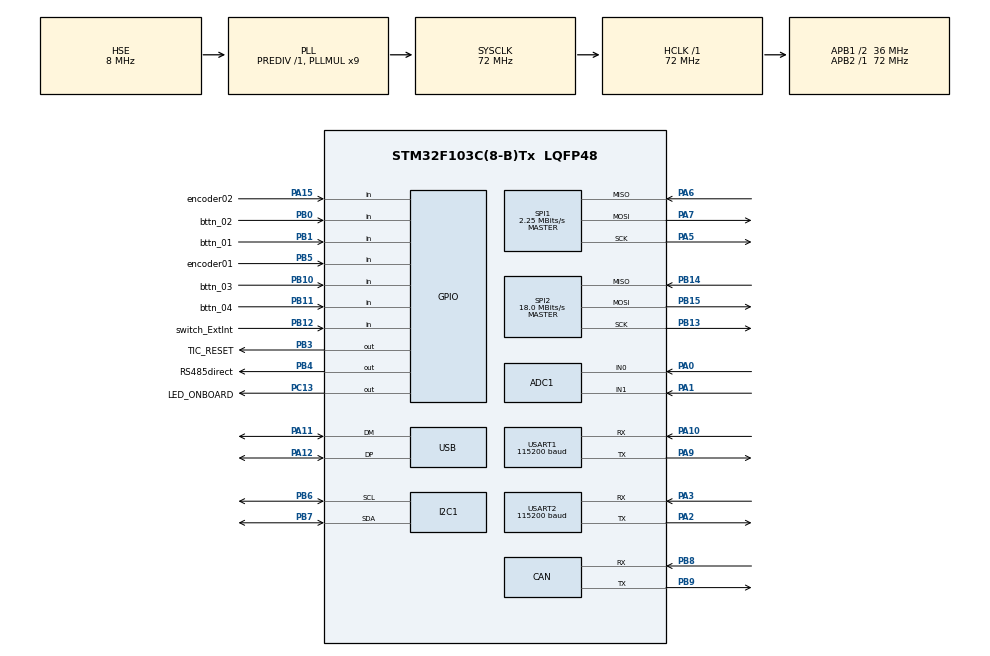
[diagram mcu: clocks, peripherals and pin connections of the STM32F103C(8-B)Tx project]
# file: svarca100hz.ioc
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ADC1.Channel-0\#ChannelRegularConversion=ADC_CHANNEL_0
ADC1.NbrOfConversionFlag=1
ADC1.Rank-0\#ChannelRegularConversion=1
ADC1.SamplingTime-0\#ChannelRegularConversion=ADC_SAMPLETIME_1CYCLE_5
ADC1.master=1
CAN.CalculateTimeBit=1333
CAN.CalculateTimeQuantum=444.44444444444446
Dma.I2C1_TX.1.Direction=DMA_MEMORY_TO_PERIPH
Dma.I2C1_TX.1.Instance=DMA1_Channel6
Dma.I2C1_TX.1.MemDataAlignment=DMA_MDATAALIGN_BYTE
Dma.I2C1_TX.1.MemInc=DMA_MINC_ENABLE
Dma.I2C1_TX.1.Mode=DMA_NORMAL
Dma.I2C1_TX.1.PeriphDataAlignment=DMA_PDATAALIGN_BYTE
Dma.I2C1_TX.1.PeriphInc=DMA_PINC_DISABLE
Dma.I2C1_TX.1.Priority=DMA_PRIORITY_LOW
Dma.Request0=SPI1_TX
Dma.Request1=I2C1_TX
Dma.SPI1_TX.0.Direction=DMA_MEMORY_TO_PERIPH
Dma.SPI1_TX.0.Instance=DMA1_Channel3
Dma.SPI1_TX.0.MemDataAlignment=DMA_MDATAALIGN_BYTE
Dma.SPI1_TX.0.MemInc=DMA_MINC_ENABLE
Dma.SPI1_TX.0.Mode=DMA_NORMAL
Dma.SPI1_TX.0.PeriphDataAlignment=DMA_PDATAALIGN_BYTE
Dma.SPI1_TX.0.PeriphInc=DMA_PINC_DISABLE
Dma.SPI1_TX.0.Priority=DMA_PRIORITY_LOW
FREERTOS.HEAP_NUMBER=1
FREERTOS.INCLUDE_vTaskDelete=0
FREERTOS.Tasks01=defaultTask,0,128,StartDefaultTask,Default,NULL,Dynamic,NULL,NULL;LedTask,0,128,StartLedTask,Default,NULL,Dynamic,NULL,NULL;lcd_Task,-2,256,Start_lcd_Task,Default,NULL,Dynamic,NULL,NULL;apl_Task,0,256,Start_apl_Task,Default,NULL,Dynamic,NULL,NULL
FREERTOS.Timers01=timer01,timer01_callback,osTimerOnce,Default,NULL,Dynamic,NULL
FREERTOS.configTOTAL_HEAP_SIZE=6000
FREERTOS.configUSE_TIMERS=1
I2C1.I2C_Mode=I2C_Standard
Mcu.Family=STM32F1
Mcu.Name=STM32F103C(8-B)Tx
Mcu.Package=LQFP48
NVIC.ADC1_2_IRQn=true\:5\:0\:false\:false\:true\:true\:true
NVIC.DMA1_Channel3_IRQn=true\:5\:0\:false\:false\:true\:true\:true
NVIC.DMA1_Channel6_IRQn=true\:5\:0\:false\:false\:true\:true\:true
NVIC.I2C1_EV_IRQn=true\:5\:0\:false\:false\:true\:true\:true
NVIC.PriorityGroup=NVIC_PRIORITYGROUP_4
NVIC.TIM1_UP_IRQn=true\:5\:0\:false\:false\:true\:true\:true
NVIC.TIM2_IRQn=true\:0\:0\:false\:false\:true\:false\:true
NVIC.TimeBase=TIM2_IRQn
NVIC.TimeBaseIP=TIM2
NVIC.USART1_IRQn=true\:5\:0\:false\:false\:true\:true\:true
NVIC.USART2_IRQn=true\:5\:0\:false\:false\:true\:true\:true
NVIC.USB_LP_CAN1_RX0_IRQn=true\:0\:0\:false\:false\:true\:false\:true
PA0-WKUP.Signal=ADCx_IN0
PA1.Signal=ADCx_IN1
PA10.Mode=Asynchronous
PA10.Signal=USART1_RX
PA11.Mode=Device
PA11.Signal=USB_DM
PA12.Mode=Device
PA12.Signal=USB_DP
PA13.Mode=Serial_Wire
PA13.Signal=SYS_JTMS-SWDIO
PA14.Mode=Serial_Wire
PA14.Signal=SYS_JTCK-SWCLK
PA15.GPIO_Label=encoder02
PA15.GPIO_PuPd=GPIO_PULLUP
PA15.Signal=GPIO_Input
PA2.Mode=Asynchronous
PA2.Signal=USART2_TX
PA3.Mode=Asynchronous
PA3.Signal=USART2_RX
PA5.Mode=Full_Duplex_Master
PA5.Signal=SPI1_SCK
PA6.Mode=Full_Duplex_Master
PA6.Signal=SPI1_MISO
PA7.Mode=Full_Duplex_Master
PA7.Signal=SPI1_MOSI
PA9.Mode=Asynchronous
PA9.Signal=USART1_TX
PB0.GPIO_Label=bttn_02
PB0.GPIO_PuPd=GPIO_PULLUP
PB0.Signal=GPIO_Input
PB1.GPIO_Label=bttn_01
PB1.GPIO_PuPd=GPIO_PULLUP
PB1.Signal=GPIO_Input
PB10.GPIO_Label=bttn_03
PB10.GPIO_PuPd=GPIO_PULLUP
PB10.Signal=GPIO_Input
PB11.GPIO_Label=bttn_04
PB11.GPIO_PuPd=GPIO_PULLUP
PB11.Signal=GPIO_Input
PB12.GPIO_Label=switch_ExtInt
PB12.GPIO_PuPd=GPIO_PULLUP
PB12.Signal=GPIO_Input
PB13.Mode=Full_Duplex_Master
PB13.Signal=SPI2_SCK
PB14.Mode=Full_Duplex_Master
PB14.Signal=SPI2_MISO
PB15.Mode=Full_Duplex_Master
PB15.Signal=SPI2_MOSI
PB3.GPIO_Label=TIC_RESET
PB3.GPIO_ModeDefaultOutputPP=GPIO_MODE_OUTPUT_PP
PB3.Signal=GPIO_Output
PB4.GPIO_Label=RS485direct
PB4.GPIO_ModeDefaultOutputPP=GPIO_MODE_OUTPUT_OD
PB4.Signal=GPIO_Output
PB5.GPIO_Label=encoder01
PB5.GPIO_PuPd=GPIO_PULLUP
PB5.Signal=GPIO_Input
PB6.Mode=I2C
PB6.Signal=I2C1_SCL
PB7.Mode=I2C
PB7.Signal=I2C1_SDA
PB8.Mode=Master
PB8.Signal=CAN_RX
PB9.Mode=Master
PB9.Signal=CAN_TX
PC13-TAMPER-RTC.GPIO_Label=LED_ONBOARD
PC13-TAMPER-RTC.GPIO_ModeDefaultOutputPP=GPIO_MODE_OUTPUT_OD
PC13-TAMPER-RTC.Signal=GPIO_Output
PC14-OSC32_IN.Mode=LSE-External-Oscillator
PC14-OSC32_IN.Signal=RCC_OSC32_IN
PC15-OSC32_OUT.Mode=LSE-External-Oscillator
PC15-OSC32_OUT.Signal=RCC_OSC32_OUT
PD0-OSC_IN.Mode=HSE-External-Oscillator
PD0-OSC_IN.Signal=RCC_OSC_IN
PD1-OSC_OUT.Mode=HSE-External-Oscillator
PD1-OSC_OUT.Signal=RCC_OSC_OUT
ProjectManager.HeapSize=0x200
ProjectManager.StackSize=0x400
ProjectManager.TargetToolchain=TrueSTUDIO
RCC.ADCPresc=RCC_ADCPCLK2_DIV6
RCC.AHBFreq_Value=72000000
RCC.APB1CLKDivider=RCC_HCLK_DIV2
RCC.APB1Freq_Value=36000000
RCC.APB1TimFreq_Value=72000000
RCC.APB2Freq_Value=72000000
RCC.APB2TimFreq_Value=72000000
RCC.HCLKFreq_Value=72000000
RCC.PLLMUL=RCC_PLL_MUL9
RCC.PLLSourceVirtual=RCC_PLLSOURCE_HSE
RCC.RTCClockSelection=RCC_RTCCLKSOURCE_LSE
RCC.SYSCLKFreq_VALUE=72000000
RCC.SYSCLKSource=RCC_SYSCLKSOURCE_PLLCLK
RCC.USBFreq_Value=48000000
RCC.USBPrescaler=RCC_USBCLKSOURCE_PLL_DIV1_5
SH.ADCx_IN0.0=ADC1_IN0,IN0
SH.ADCx_IN1.0=ADC1_IN1,IN1
SPI1.BaudRatePrescaler=SPI_BAUDRATEPRESCALER_32
SPI1.CLKPhase=SPI_PHASE_2EDGE
SPI1.CalculateBaudRate=2.25 MBits/s
SPI1.Direction=SPI_DIRECTION_2LINES
SPI1.Mode=SPI_MODE_MASTER
SPI1.VirtualType=VM_MASTER
SPI2.CalculateBaudRate=18.0 MBits/s
SPI2.Direction=SPI_DIRECTION_2LINES
SPI2.Mode=SPI_MODE_MASTER
SPI2.VirtualType=VM_MASTER
TIM1.Period=60000
TIM1.Prescaler=100
USART1.BaudRate=115200
USART1.VirtualMode=VM_ASYNC
USART2.BaudRate=115200
USART2.VirtualMode=VM_ASYNC
USB_DEVICE.CLASS_NAME_FS=CDC
USB_DEVICE.VirtualMode=Cdc
USB_DEVICE.VirtualModeFS=Cdc_FS
VP_FREERTOS_VS_ENABLE.Mode=Enabled
VP_SYS_VS_tim2.Mode=TIM2
VP_TIM1_VS_ClockSourceINT.Mode=Internal
VP_USB_DEVICE_VS_USB_DEVICE_CDC_FS.Mode=CDC_FS
board=Ravenizer

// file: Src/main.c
/* USER CODE BEGIN Header */
/**
  ******************************************************************************
  * @file           : main.c
  * @brief          : Main program body
  ******************************************************************************
  * This notice applies to any and all portions of this file
  * that are not between comment pairs USER CODE BEGIN and
  * USER CODE END. Other portions of this file, whether
  * inserted by the user or by software development tools
  * are owned by their respective copyright owners.
  *
  * Copyright (c) 2019 STMicroelectronics International N.V.
  * All rights reserved.
  *
  * Redistribution and use in source and binary forms, with or without
  * modification, are permitted, provided that the following conditions are met:
  *
  * 1. Redistribution of source code must retain the above copyright notice,
  *    this list of conditions and the following disclaimer.
  * 2. Redistributions in binary form must reproduce the above copyright notice,
  *    this list of conditions and the following disclaimer in the documentation
  *    and/or other materials provided with the distribution.
  * 3. Neither the name of STMicroelectronics nor the names of other
  *    contributors to this software may be used to endorse or promote products
  *    derived from this software without specific written permission.
  * 4. This software, including modifications and/or derivative works of this
  *    software, must execute solely and exclusively on microcontroller or
  *    microprocessor devices manufactured by or for STMicroelectronics.
  * 5. Redistribution and use of this software other than as permitted under
  *    this license is void and will automatically terminate your rights under
  *    this license.
  *
  * THIS SOFTWARE IS PROVIDED BY STMICROELECTRONICS AND CONTRIBUTORS "AS IS"
  * AND ANY EXPRESS, IMPLIED OR STATUTORY WARRANTIES, INCLUDING, BUT NOT
  * LIMITED TO, THE IMPLIED WARRANTIES OF MERCHANTABILITY, FITNESS FOR A
  * PARTICULAR PURPOSE AND NON-INFRINGEMENT OF THIRD PARTY INTELLECTUAL PROPERTY
  * RIGHTS ARE DISCLAIMED TO THE FULLEST EXTENT PERMITTED BY LAW. IN NO EVENT
  * SHALL STMICROELECTRONICS OR CONTRIBUTORS BE LIABLE FOR ANY DIRECT, INDIRECT,
  * INCIDENTAL, SPECIAL, EXEMPLARY, OR CONSEQUENTIAL DAMAGES (INCLUDING, BUT NOT
  * LIMITED TO, PROCUREMENT OF SUBSTITUTE GOODS OR SERVICES; LOSS OF USE, DATA,
  * OR PROFITS; OR BUSINESS INTERRUPTION) HOWEVER CAUSED AND ON ANY THEORY OF
  * LIABILITY, WHETHER IN CONTRACT, STRICT LIABILITY, OR TORT (INCLUDING
  * NEGLIGENCE OR OTHERWISE) ARISING IN ANY WAY OUT OF THE USE OF THIS SOFTWARE,
  * EVEN IF ADVISED OF THE POSSIBILITY OF SUCH DAMAGE.
  *
  ******************************************************************************
  */
/* USER CODE END Header */

#include "main.h"
#include "cmsis_os.h"
#include "usb_device.h"

ADC_HandleTypeDef hadc1;

CAN_HandleTypeDef hcan;

I2C_HandleTypeDef hi2c1;
DMA_HandleTypeDef hdma_i2c1_tx;

SPI_HandleTypeDef hspi1;
SPI_HandleTypeDef hspi2;
DMA_HandleTypeDef hdma_spi1_tx;

TIM_HandleTypeDef htim1;

UART_HandleTypeDef huart1;
UART_HandleTypeDef huart2;

osThreadId defaultTaskHandle;
osThreadId LedTaskHandle;
osThreadId lcd_TaskHandle;
osThreadId apl_TaskHandle;
osTimerId timer01Handle;

void SystemClock_Config(void);
static void MX_GPIO_Init(void);
static void MX_DMA_Init(void);
static void MX_TIM1_Init(void);
static void MX_USART1_UART_Init(void);
static void MX_USART2_UART_Init(void);
static void MX_SPI1_Init(void);
static void MX_I2C1_Init(void);
static void MX_SPI2_Init(void);
static void MX_CAN_Init(void);
static void MX_ADC1_Init(void);
void StartDefaultTask(void const * argument);
void StartLedTask(void const * argument);
void Start_lcd_Task(void const * argument);
void Start_apl_Task(void const * argument);
void timer01_callback(void const * argument);

int main(void)
{

  /* MCU Configuration--------------------------------------------------------*/

  /* Reset of all peripherals, Initializes the Flash interface and the Systick. */
  HAL_Init();

  /* Configure the system clock */
  SystemClock_Config();

  /* Initialize all configured peripherals */
  MX_GPIO_Init();
  MX_DMA_Init();
  MX_TIM1_Init();
  MX_USART1_UART_Init();
  MX_USART2_UART_Init();
  MX_SPI1_Init();
  MX_I2C1_Init();
  MX_SPI2_Init();
  MX_CAN_Init();
  MX_ADC1_Init();

  /* Create the timer(s) */
  /* definition and creation of timer01 */
  osTimerDef(timer01, timer01_callback);
  timer01Handle = osTimerCreate(osTimer(timer01), osTimerOnce, NULL);

  /* Create the thread(s) */
  /* definition and creation of defaultTask */
  osThreadDef(defaultTask, StartDefaultTask, osPriorityNormal, 0, 128);
  defaultTaskHandle = osThreadCreate(osThread(defaultTask), NULL);

  /* definition and creation of LedTask */
  osThreadDef(LedTask, StartLedTask, osPriorityNormal, 0, 128);
  LedTaskHandle = osThreadCreate(osThread(LedTask), NULL);

  /* definition and creation of lcd_Task */
  osThreadDef(lcd_Task, Start_lcd_Task, osPriorityLow, 0, 256);
  lcd_TaskHandle = osThreadCreate(osThread(lcd_Task), NULL);

  /* definition and creation of apl_Task */
  osThreadDef(apl_Task, Start_apl_Task, osPriorityNormal, 0, 256);
  apl_TaskHandle = osThreadCreate(osThread(apl_Task), NULL);

  /* Start scheduler */
  osKernelStart();

  /* We should never get here as control is now taken by the scheduler */

  /* Infinite loop */
  while (1)
  {

  }
}

void SystemClock_Config(void)
{
  RCC_OscInitTypeDef RCC_OscInitStruct = {0};
  RCC_ClkInitTypeDef RCC_ClkInitStruct = {0};
  RCC_PeriphCLKInitTypeDef PeriphClkInit = {0};

  /**Initializes the CPU, AHB and APB busses clocks
  */
  RCC_OscInitStruct.OscillatorType = RCC_OSCILLATORTYPE_HSE;
  RCC_OscInitStruct.HSEState = RCC_HSE_ON;
  RCC_OscInitStruct.HSEPredivValue = RCC_HSE_PREDIV_DIV1;
  RCC_OscInitStruct.HSIState = RCC_HSI_ON;
  RCC_OscInitStruct.PLL.PLLState = RCC_PLL_ON;
  RCC_OscInitStruct.PLL.PLLSource = RCC_PLLSOURCE_HSE;
  RCC_OscInitStruct.PLL.PLLMUL = RCC_PLL_MUL9;
  if (HAL_RCC_OscConfig(&RCC_OscInitStruct) != HAL_OK)
  {
    Error_Handler();
  }
  /**Initializes the CPU, AHB and APB busses clocks
  */
  RCC_ClkInitStruct.ClockType = RCC_CLOCKTYPE_HCLK|RCC_CLOCKTYPE_SYSCLK
                              |RCC_CLOCKTYPE_PCLK1|RCC_CLOCKTYPE_PCLK2;
  RCC_ClkInitStruct.SYSCLKSource = RCC_SYSCLKSOURCE_PLLCLK;
  RCC_ClkInitStruct.AHBCLKDivider = RCC_SYSCLK_DIV1;
  RCC_ClkInitStruct.APB1CLKDivider = RCC_HCLK_DIV2;
  RCC_ClkInitStruct.APB2CLKDivider = RCC_HCLK_DIV1;

  if (HAL_RCC_ClockConfig(&RCC_ClkInitStruct, FLASH_LATENCY_2) != HAL_OK)
  {
    Error_Handler();
  }
  PeriphClkInit.PeriphClockSelection = RCC_PERIPHCLK_ADC|RCC_PERIPHCLK_USB;
  PeriphClkInit.AdcClockSelection = RCC_ADCPCLK2_DIV6;
  PeriphClkInit.UsbClockSelection = RCC_USBCLKSOURCE_PLL_DIV1_5;
  if (HAL_RCCEx_PeriphCLKConfig(&PeriphClkInit) != HAL_OK)
  {
    Error_Handler();
  }
}

static void MX_ADC1_Init(void)
{

  ADC_ChannelConfTypeDef sConfig = {0};

  /**Common config
  */
  hadc1.Instance = ADC1;
  hadc1.Init.ScanConvMode = ADC_SCAN_DISABLE;
  hadc1.Init.ContinuousConvMode = DISABLE;
  hadc1.Init.DiscontinuousConvMode = DISABLE;
  hadc1.Init.ExternalTrigConv = ADC_SOFTWARE_START;
  hadc1.Init.DataAlign = ADC_DATAALIGN_RIGHT;
  hadc1.Init.NbrOfConversion = 1;
  if (HAL_ADC_Init(&hadc1) != HAL_OK)
  {
    Error_Handler();
  }
  /**Configure Regular Channel
  */
  sConfig.Channel = ADC_CHANNEL_0;
  sConfig.Rank = ADC_REGULAR_RANK_1;
  sConfig.SamplingTime = ADC_SAMPLETIME_1CYCLE_5;
  if (HAL_ADC_ConfigChannel(&hadc1, &sConfig) != HAL_OK)
  {
    Error_Handler();
  }

}

static void MX_CAN_Init(void)
{

  hcan.Instance = CAN1;
  hcan.Init.Prescaler = 16;
  hcan.Init.Mode = CAN_MODE_NORMAL;
  hcan.Init.SyncJumpWidth = CAN_SJW_1TQ;
  hcan.Init.TimeSeg1 = CAN_BS1_1TQ;
  hcan.Init.TimeSeg2 = CAN_BS2_1TQ;
  hcan.Init.TimeTriggeredMode = DISABLE;
  hcan.Init.AutoBusOff = DISABLE;
  hcan.Init.AutoWakeUp = DISABLE;
  hcan.Init.AutoRetransmission = DISABLE;
  hcan.Init.ReceiveFifoLocked = DISABLE;
  hcan.Init.TransmitFifoPriority = DISABLE;
  if (HAL_CAN_Init(&hcan) != HAL_OK)
  {
    Error_Handler();
  }

}

static void MX_I2C1_Init(void)
{

  hi2c1.Instance = I2C1;
  hi2c1.Init.ClockSpeed = 100000;
  hi2c1.Init.DutyCycle = I2C_DUTYCYCLE_2;
  hi2c1.Init.OwnAddress1 = 0;
  hi2c1.Init.AddressingMode = I2C_ADDRESSINGMODE_7BIT;
  hi2c1.Init.DualAddressMode = I2C_DUALADDRESS_DISABLE;
  hi2c1.Init.OwnAddress2 = 0;
  hi2c1.Init.GeneralCallMode = I2C_GENERALCALL_DISABLE;
  hi2c1.Init.NoStretchMode = I2C_NOSTRETCH_DISABLE;
  if (HAL_I2C_Init(&hi2c1) != HAL_OK)
  {
    Error_Handler();
  }

}

static void MX_SPI1_Init(void)
{

  /* SPI1 parameter configuration*/
  hspi1.Instance = SPI1;
  hspi1.Init.Mode = SPI_MODE_MASTER;
  hspi1.Init.Direction = SPI_DIRECTION_2LINES;
  hspi1.Init.DataSize = SPI_DATASIZE_8BIT;
  hspi1.Init.CLKPolarity = SPI_POLARITY_LOW;
  hspi1.Init.CLKPhase = SPI_PHASE_2EDGE;
  hspi1.Init.NSS = SPI_NSS_SOFT;
  hspi1.Init.BaudRatePrescaler = SPI_BAUDRATEPRESCALER_32;
  hspi1.Init.FirstBit = SPI_FIRSTBIT_MSB;
  hspi1.Init.TIMode = SPI_TIMODE_DISABLE;
  hspi1.Init.CRCCalculation = SPI_CRCCALCULATION_DISABLE;
  hspi1.Init.CRCPolynomial = 10;
  if (HAL_SPI_Init(&hspi1) != HAL_OK)
  {
    Error_Handler();
  }

}

static void MX_SPI2_Init(void)
{

  /* SPI2 parameter configuration*/
  hspi2.Instance = SPI2;
  hspi2.Init.Mode = SPI_MODE_MASTER;
  hspi2.Init.Direction = SPI_DIRECTION_2LINES;
  hspi2.Init.DataSize = SPI_DATASIZE_8BIT;
  hspi2.Init.CLKPolarity = SPI_POLARITY_LOW;
  hspi2.Init.CLKPhase = SPI_PHASE_1EDGE;
  hspi2.Init.NSS = SPI_NSS_SOFT;
  hspi2.Init.BaudRatePrescaler = SPI_BAUDRATEPRESCALER_2;
  hspi2.Init.FirstBit = SPI_FIRSTBIT_MSB;
  hspi2.Init.TIMode = SPI_TIMODE_DISABLE;
  hspi2.Init.CRCCalculation = SPI_CRCCALCULATION_DISABLE;
  hspi2.Init.CRCPolynomial = 10;
  if (HAL_SPI_Init(&hspi2) != HAL_OK)
  {
    Error_Handler();
  }

}

static void MX_TIM1_Init(void)
{

  TIM_ClockConfigTypeDef sClockSourceConfig = {0};
  TIM_MasterConfigTypeDef sMasterConfig = {0};

  htim1.Instance = TIM1;
  htim1.Init.Prescaler = 100;
  htim1.Init.CounterMode = TIM_COUNTERMODE_UP;
  htim1.Init.Period = 60000;
  htim1.Init.ClockDivision = TIM_CLOCKDIVISION_DIV1;
  htim1.Init.RepetitionCounter = 0;
  htim1.Init.AutoReloadPreload = TIM_AUTORELOAD_PRELOAD_DISABLE;
  if (HAL_TIM_Base_Init(&htim1) != HAL_OK)
  {
    Error_Handler();
  }
  sClockSourceConfig.ClockSource = TIM_CLOCKSOURCE_INTERNAL;
  if (HAL_TIM_ConfigClockSource(&htim1, &sClockSourceConfig) != HAL_OK)
  {
    Error_Handler();
  }
  sMasterConfig.MasterOutputTrigger = TIM_TRGO_RESET;
  sMasterConfig.MasterSlaveMode = TIM_MASTERSLAVEMODE_DISABLE;
  if (HAL_TIMEx_MasterConfigSynchronization(&htim1, &sMasterConfig) != HAL_OK)
  {
    Error_Handler();
  }

}

static void MX_USART1_UART_Init(void)
{

  huart1.Instance = USART1;
  huart1.Init.BaudRate = 115200;
  huart1.Init.WordLength = UART_WORDLENGTH_8B;
  huart1.Init.StopBits = UART_STOPBITS_1;
  huart1.Init.Parity = UART_PARITY_NONE;
  huart1.Init.Mode = UART_MODE_TX_RX;
  huart1.Init.HwFlowCtl = UART_HWCONTROL_NONE;
  huart1.Init.OverSampling = UART_OVERSAMPLING_16;
  if (HAL_UART_Init(&huart1) != HAL_OK)
  {
    Error_Handler();
  }

}

static void MX_USART2_UART_Init(void)
{

  huart2.Instance = USART2;
  huart2.Init.BaudRate = 115200;
  huart2.Init.WordLength = UART_WORDLENGTH_8B;
  huart2.Init.StopBits = UART_STOPBITS_1;
  huart2.Init.Parity = UART_PARITY_NONE;
  huart2.Init.Mode = UART_MODE_TX_RX;
  huart2.Init.HwFlowCtl = UART_HWCONTROL_NONE;
  huart2.Init.OverSampling = UART_OVERSAMPLING_16;
  if (HAL_UART_Init(&huart2) != HAL_OK)
  {
    Error_Handler();
  }

}

static void MX_DMA_Init(void)
{
  /* DMA controller clock enable */
  __HAL_RCC_DMA1_CLK_ENABLE();

  /* DMA interrupt init */
  /* DMA1_Channel3_IRQn interrupt configuration */
  HAL_NVIC_SetPriority(DMA1_Channel3_IRQn, 5, 0);
  HAL_NVIC_EnableIRQ(DMA1_Channel3_IRQn);
  /* DMA1_Channel6_IRQn interrupt configuration */
  HAL_NVIC_SetPriority(DMA1_Channel6_IRQn, 5, 0);
  HAL_NVIC_EnableIRQ(DMA1_Channel6_IRQn);

}

static void MX_GPIO_Init(void)
{
  GPIO_InitTypeDef GPIO_InitStruct = {0};

  /* GPIO Ports Clock Enable */
  __HAL_RCC_GPIOC_CLK_ENABLE();
  __HAL_RCC_GPIOD_CLK_ENABLE();
  __HAL_RCC_GPIOA_CLK_ENABLE();
  __HAL_RCC_GPIOB_CLK_ENABLE();

  /*Configure GPIO pin Output Level */
  HAL_GPIO_WritePin(LED_ONBOARD_GPIO_Port, LED_ONBOARD_Pin, GPIO_PIN_RESET);

  /*Configure GPIO pin Output Level */
  HAL_GPIO_WritePin(GPIOB, TIC_RESET_Pin|RS485direct_Pin, GPIO_PIN_RESET);

  /*Configure GPIO pin : LED_ONBOARD_Pin */
  GPIO_InitStruct.Pin = LED_ONBOARD_Pin;
  GPIO_InitStruct.Mode = GPIO_MODE_OUTPUT_OD;
  GPIO_InitStruct.Pull = GPIO_NOPULL;
  GPIO_InitStruct.Speed = GPIO_SPEED_FREQ_LOW;
  HAL_GPIO_Init(LED_ONBOARD_GPIO_Port, &GPIO_InitStruct);

  /*Configure GPIO pins : bttn_02_Pin bttn_01_Pin bttn_03_Pin bttn_04_Pin
                           switch_ExtInt_Pin encoder01_Pin */
  GPIO_InitStruct.Pin = bttn_02_Pin|bttn_01_Pin|bttn_03_Pin|bttn_04_Pin
                          |switch_ExtInt_Pin|encoder01_Pin;
  GPIO_InitStruct.Mode = GPIO_MODE_INPUT;
  GPIO_InitStruct.Pull = GPIO_PULLUP;
  HAL_GPIO_Init(GPIOB, &GPIO_InitStruct);

  /*Configure GPIO pin : encoder02_Pin */
  GPIO_InitStruct.Pin = encoder02_Pin;
  GPIO_InitStruct.Mode = GPIO_MODE_INPUT;
  GPIO_InitStruct.Pull = GPIO_PULLUP;
  HAL_GPIO_Init(encoder02_GPIO_Port, &GPIO_InitStruct);

  /*Configure GPIO pin : TIC_RESET_Pin */
  GPIO_InitStruct.Pin = TIC_RESET_Pin;
  GPIO_InitStruct.Mode = GPIO_MODE_OUTPUT_PP;
  GPIO_InitStruct.Pull = GPIO_NOPULL;
  GPIO_InitStruct.Speed = GPIO_SPEED_FREQ_LOW;
  HAL_GPIO_Init(TIC_RESET_GPIO_Port, &GPIO_InitStruct);

  /*Configure GPIO pin : RS485direct_Pin */
  GPIO_InitStruct.Pin = RS485direct_Pin;
  GPIO_InitStruct.Mode = GPIO_MODE_OUTPUT_OD;
  GPIO_InitStruct.Pull = GPIO_NOPULL;
  GPIO_InitStruct.Speed = GPIO_SPEED_FREQ_LOW;
  HAL_GPIO_Init(RS485direct_GPIO_Port, &GPIO_InitStruct);

}

/* USER CODE BEGIN 4 */

void Onboard_led_ON(void){
    HAL_GPIO_WritePin(LED_ONBOARD_GPIO_Port, LED_ONBOARD_Pin, GPIO_PIN_RESET);
}

void Onboard_led_OFF(void){
    HAL_GPIO_WritePin(LED_ONBOARD_GPIO_Port, LED_ONBOARD_Pin, GPIO_PIN_SET);
}

void Onboard_led_TOGG(void){
    HAL_GPIO_TogglePin(LED_ONBOARD_GPIO_Port, LED_ONBOARD_Pin);
}

uint32_t adcval;

void HAL_ADC_ConvCpltCallback(ADC_HandleTypeDef* hadc)
{
    adcval = HAL_ADC_GetValue(hadc);
}

/* USER CODE END 4 */

void StartDefaultTask(void const * argument)
{
  /* init code for USB_DEVICE */
  MX_USB_DEVICE_Init();

  for(;;)
  {
    osDelay(1);
  }
}

void StartLedTask(void const * argument)
{
  /* USER CODE BEGIN StartLedTask */
  /* Infinite loop */
  for(;;)
  {
    HAL_ADC_Start_IT(&hadc1);

    //counter++;
    gui_print_param1(adcval);
    Onboard_led_TOGG();
    osDelay(300);
  }
  /* USER CODE END StartLedTask */
}

void Start_lcd_Task(void const * argument)
{
  /* USER CODE BEGIN Start_lcd_Task */
  /* Infinite loop */
  for(;;)
  {
      lcd_Task();
  }
  /* USER CODE END Start_lcd_Task */
}

void Start_apl_Task(void const * argument)
{
  for(;;)
  {
    osDelay(1);
  }
}

/* timer01_callback function */
void timer01_callback(void const * argument)
{
}

void HAL_TIM_PeriodElapsedCallback(TIM_HandleTypeDef *htim)
{
  if (htim->Instance == TIM2) {
    HAL_IncTick();
  }
}

void Error_Handler(void)
{
}

/************************ (C) COPYRIGHT STMicroelectronics *****END OF FILE****/
